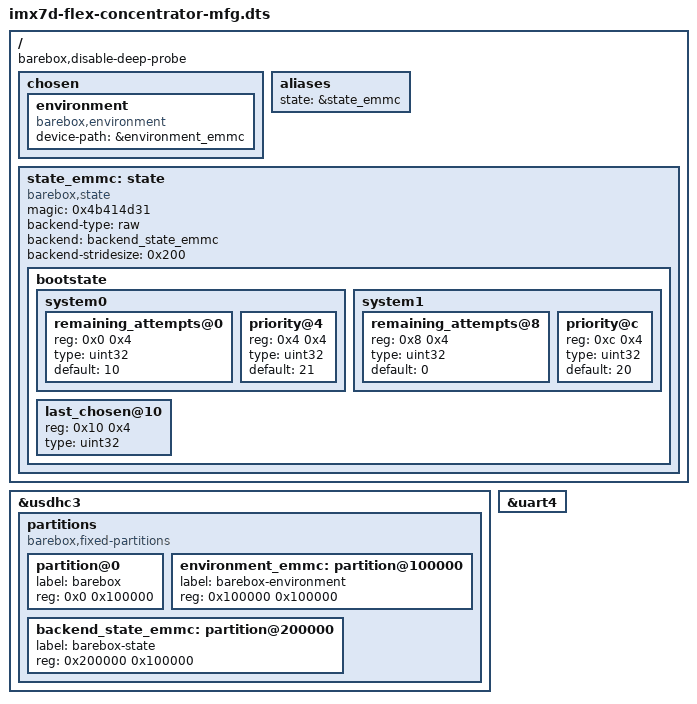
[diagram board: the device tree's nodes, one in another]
/*
 * The code contained herein is licensed under the GNU General Public
 * License. You may obtain a copy of the GNU General Public License
 * Version 2 or later at the following locations:
 *
 * http://www.opensource.org/licenses/gpl-license.html
 * http://www.gnu.org/copyleft/gpl.html
 */

#include <arm/nxp/imx/imx7d-flex-concentrator-mfg.dts>

/ {
	barebox,disable-deep-probe;

	chosen {
		environment {
			compatible = "barebox,environment";
			device-path = &environment_emmc;
		};
	};

	aliases {
		state = &state_emmc;
	};

	state_emmc: state {
		#address-cells = <1>;
		#size-cells = <1>;
		compatible = "barebox,state";
		magic = <0x4b414d31>;
		backend-type = "raw";
		backend = <&backend_state_emmc>;
		backend-stridesize = <0x200>;

		bootstate {
			#address-cells = <1>;
			#size-cells = <1>;

			system0 {
				#address-cells = <1>;
				#size-cells = <1>;

				remaining_attempts@0 {
					reg = <0x0 0x4>;
					type = "uint32";
					default = <10>;
				};

				priority@4 {
					reg = <0x4 0x4>;
					type = "uint32";
					default = <21>;
				};
			};

			system1 {
				#address-cells = <1>;
				#size-cells = <1>;

				remaining_attempts@8 {
					reg = <0x8 0x4>;
					type = "uint32";
					default = <0>;
				};

				priority@c {
					reg = <0xc 0x4>;
					type = "uint32";
					default = <20>;
				};
			};

			last_chosen@10 {
				reg = <0x10 0x4>;
				type = "uint32";
			};
		};
	};
};

/* eMMC */
&usdhc3 {
	partitions {
		compatible = "barebox,fixed-partitions";
		#address-cells = <1>;
		#size-cells = <1>;

		partition@0 {
			label = "barebox";
			reg = <0x0 0x100000>;
		};

		environment_emmc: partition@100000 {
			label = "barebox-environment";
			reg = <0x100000 0x100000>;
		};

		backend_state_emmc: partition@200000 {
			label = "barebox-state";
			reg = <0x200000 0x100000>;
		};
	};
};

/* FIXME: barebox serial is broken when barebox applies requested reparenting */
&uart4 {
	/delete-property/ assigned-clocks;
	/delete-property/ assigned-clock-parents;
};

